AUTOSAR XML (schema 00048)
package /HuaweiMDC/FunctionalSoftware/RadarDetectionApplication/Execution
  executable RadarDetectionExecutable
    root sw component prototype RadarDetectionRootSwComponent: application-type=RadarDetectionApplicationSwComponent
package /HuaweiMDC/FunctionalSoftware/RadarDetectionApplication/SwComponent
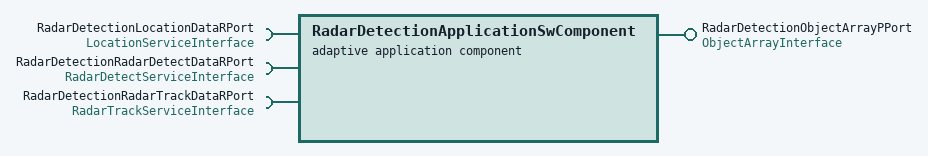
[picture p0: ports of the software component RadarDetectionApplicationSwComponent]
  adaptive application sw component type RadarDetectionApplicationSwComponent
    require port RadarDetectionLocationDataRPort: required-interface=LocationServiceInterface
    provide port RadarDetectionObjectArrayPPort: provided-interface=ObjectArrayInterface
    require port RadarDetectionRadarDetectDataRPort: required-interface=RadarDetectServiceInterface
    require port RadarDetectionRadarTrackDataRPort: required-interface=RadarTrackServiceInterface
